AUTOSAR XML (schema 4.0)
standard types defined: float32, float64, sint16, sint32, sint8, uint16, uint32, uint8, void, boolean
package /ImplDataTypes
  7 x impl type, all with category=TYPE_REFERENCE, type-emitter=RTE:
    IoWeightSensorReadingType: implementation-data-type=uint16
    IopositionSensorReadingType: implementation-data-type=uint8
    SeatControlBtnImpType: implementation-data-type=uint8
    SeatControlDataImpType: implementation-data-type=uint8
    SensorPositionType: implementation-data-type=uint8
    SensorWeightType: implementation-data-type=uint8
    SepMotorStepType: implementation-data-type=sint8
package /MappingSets
  data type mapping set MappingSet
package /PortInterfaces/ClientServer
  6 x client server interface:
    CsIf_IoGetSensorPosition
      operation IoGetHeight
        arg Position: type=IopositionSensorReadingType, direction=OUT
      operation IoGetIncline
        arg Position: type=IopositionSensorReadingType, direction=OUT
      operation IoGetSlide
        arg Position: type=IopositionSensorReadingType, direction=OUT
    CsIf_IoGetSensorweight
      operation IoGetWeight
        arg weight: type=IoWeightSensorReadingType, direction=OUT
    CsIf_IoSetMotor
      6 x operation:
        IoSetHeightForward
        IoSetHeightReverse
        IoSetInclineForward
        IoSetInclineReverse
        IoSetSlideForward
        IoSetSlideReverse
    CsIf_PositionSensor
      operation GetHeightPosition
        arg Position: type=SensorPositionType, direction=OUT
      operation GetInclinePosition
        arg Position: type=SensorPositionType, direction=OUT
      operation GetSlidePosition
        arg Position: type=SensorPositionType, direction=OUT
    CsIf_StepMotor
      operation HeightMotor_Move
        arg Step: type=SepMotorStepType, direction=IN
      operation InclineMotor_Move
        arg Step: type=SepMotorStepType, direction=IN
      operation SlideMotor_Move
        arg Step: type=SepMotorStepType, direction=IN
    CsIf_WeightSensor
      operation GetWeight
        arg Weight: type=SensorWeightType, direction=OUT
package /PortInterfaces/SenderReceiver
  sender receiver interface Srlf_SeatControlBtnstate
    data HeightBtnState: type=SeatControlBtnImpType
    data InclineBtnState: type=SeatControlBtnImpType
    data SlideBtnState: type=SeatControlBtnImpType
  sender receiver interface Srlf_SeatControlData
    data HeightCtrlData: type=SeatControlDataImpType
    data InclineCtrlData: type=SeatControlDataImpType
    data SlideCtrlData: type=SeatControlDataImpType
package /SoftwareComponents
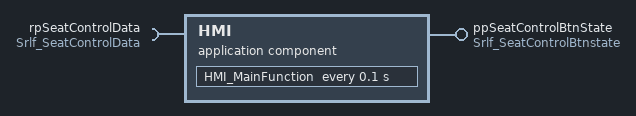
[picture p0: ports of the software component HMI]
  application sw component type HMI
    provide port ppSeatControlBtnState: provided-interface=Srlf_SeatControlBtnstate
    require port rpSeatControlData: required-interface=Srlf_SeatControlData
    behavior Ibhv_HMI: data-type-mapping=MappingSet, handle-termination-and-restart=NO-SUPPORT
      timing event TE_HMI_MainFunction_100ms: start-on-event=HMI_MainFunction, period=0.1
      runnable HMI_MainFunction
        data-receive-point-by-arguments:
          access DRP_rpSeatControlData_HeightCtrlData: accessed-variable=rpSeatControlData.HeightCtrlData
          access DRP_rpSeatControlData_InclineCtrlData: accessed-variable=rpSeatControlData.InclineCtrlData
          access DRP_rpSeatControlData_SlideCtrlData: accessed-variable=rpSeatControlData.SlideCtrlData
        data-send-points:
          access DSP_ppSeatControlBtnState_HeightBtnState: accessed-variable=ppSeatControlBtnState.HeightBtnState
          access DSP_ppSeatControlBtnState_InclineBtnState: accessed-variable=ppSeatControlBtnState.InclineBtnState
          access DSP_ppSeatControlBtnState_SlideBtnState: accessed-variable=ppSeatControlBtnState.SlideBtnState
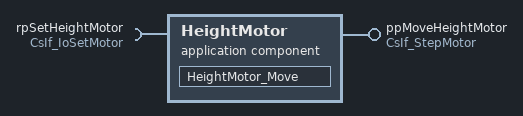
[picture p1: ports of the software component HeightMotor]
  application sw component type HeightMotor
    provide port ppMoveHeightMotor: provided-interface=CsIf_StepMotor
    require port rpSetHeightMotor: required-interface=CsIf_IoSetMotor
    behavior Ibhv_HeightMotor: data-type-mapping=MappingSet, handle-termination-and-restart=NO-SUPPORT
      operation invoked event OIE_ppMoveHeightMotor_HeightMotor_Move: start-on-event=HeightMotor_Move, operation=ppMoveHeightMotor.HeightMotor_Move
      runnable HeightMotor_Move
        sync call SCP_rpSetHeightMotor_IoSetHeightForward: operation=rpSetHeightMotor.IoSetHeightForward, timeout=0.0
        sync call SCP_rpSetHeightMotor_IoSetHeightReverse: operation=rpSetHeightMotor.IoSetHeightReverse, timeout=0.0
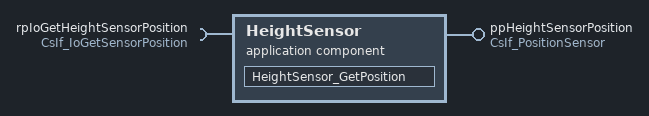
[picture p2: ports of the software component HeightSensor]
  application sw component type HeightSensor
    provide port ppHeightSensorPosition: provided-interface=CsIf_PositionSensor
    require port rpIoGetHeightSensorPosition: required-interface=CsIf_IoGetSensorPosition
    behavior Ibhv_HeightSensor: data-type-mapping=MappingSet, handle-termination-and-restart=NO-SUPPORT
      operation invoked event OIE_ppHeightSensorPosition_GetHeightPosition: start-on-event=HeightSensor_GetPosition, operation=ppHeightSensorPosition.GetHeightPosition
      runnable HeightSensor_GetPosition
        sync call SCP_rpIoGetHeightSensorPosition_IoGetHeight: operation=rpIoGetHeightSensorPosition.IoGetHeight, timeout=0.0
  10 x swc implementation, all with programming-language=C, sw-version=1.0.0, vendor-id=255:
    Impl_HMI: behavior=Ibhv_HMI
      code-descriptors:
        code Code: artifact-descriptors=autosar-engineering-object={short-label=SWC.c, category=SWSRC}
      resource consumption ResourceConsumption
    Impl_HeightMotor: behavior=Ibhv_HeightMotor
      code-descriptors:
        code Code: artifact-descriptors=autosar-engineering-object={short-label=SWC.c, category=SWSRC}
      resource consumption ResourceConsumption
    Impl_HeightSensor: behavior=Ibhv_HeightSensor
      code-descriptors:
        code Code: artifact-descriptors=autosar-engineering-object={short-label=SWC.c, category=SWSRC}
      resource consumption ResourceConsumption
    Impl_InclineMotor: behavior=Ibhv_InclineMotor
      code-descriptors:
        code Code: artifact-descriptors=autosar-engineering-object={short-label=SWC.c, category=SWSRC}
      resource consumption ResourceConsumption
    Impl_InclineSensor: behavior=Ibhv_InclineSensor
      code-descriptors:
        code Code: artifact-descriptors=autosar-engineering-object={short-label=SWC.c, category=SWSRC}
      resource consumption ResourceConsumption
    Impl_IoHwAbs: behavior=Ibhv_IoHwAbs
      code-descriptors:
        code Code: artifact-descriptors=autosar-engineering-object={short-label=SWC.c, category=SWSRC}
      resource consumption ResourceConsumption
    Impl_Seat_Manager: behavior=Ibhv_Seat_Manager
      code-descriptors:
        code Code: artifact-descriptors=autosar-engineering-object={short-label=SWC.c, category=SWSRC}
      resource consumption ResourceConsumption
    Impl_SlideMotor: behavior=Ibhv_SlideMotor
      code-descriptors:
        code Code: artifact-descriptors=autosar-engineering-object={short-label=SWC.c, category=SWSRC}
      resource consumption ResourceConsumption
    Impl_SlideSensor: behavior=Ibhv_SlideSensor
      code-descriptors:
        code Code: artifact-descriptors=autosar-engineering-object={short-label=SWC.c, category=SWSRC}
      resource consumption ResourceConsumption
    Impl_WeightSensor: behavior=Ibhv_WeightSensor
      code-descriptors:
        code Code: artifact-descriptors=autosar-engineering-object={short-label=SWC.c, category=SWSRC}
      resource consumption ResourceConsumption
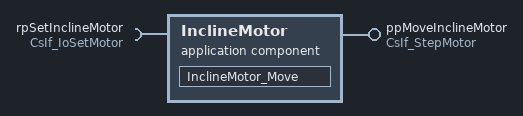
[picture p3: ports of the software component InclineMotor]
  application sw component type InclineMotor
    provide port ppMoveInclineMotor: provided-interface=CsIf_StepMotor
    require port rpSetInclineMotor: required-interface=CsIf_IoSetMotor
    behavior Ibhv_InclineMotor: data-type-mapping=MappingSet, handle-termination-and-restart=NO-SUPPORT
      operation invoked event OIE_ppMoveInclineMotor_InclineMotor_Move: start-on-event=InclineMotor_Move, operation=ppMoveInclineMotor.InclineMotor_Move
      runnable InclineMotor_Move
        sync call SCP_rpSetInclineMotor_IoSetInclineForward: operation=rpSetInclineMotor.IoSetInclineForward, timeout=0.0
        sync call SCP_rpSetInclineMotor_IoSetInclineReverse: operation=rpSetInclineMotor.IoSetInclineReverse, timeout=0.0
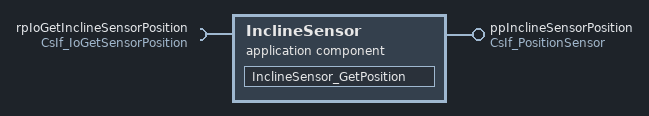
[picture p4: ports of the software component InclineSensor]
  application sw component type InclineSensor
    provide port ppInclineSensorPosition: provided-interface=CsIf_PositionSensor
    require port rpIoGetInclineSensorPosition: required-interface=CsIf_IoGetSensorPosition
    behavior Ibhv_InclineSensor: data-type-mapping=MappingSet, handle-termination-and-restart=NO-SUPPORT
      operation invoked event OIE_ppInclineSensorPosition_GetInclinePosition: start-on-event=InclineSensor_GetPosition, operation=ppInclineSensorPosition.GetInclinePosition
      runnable InclineSensor_GetPosition
        sync call SCP_rpIoGetInclineSensorPosition_IoGetIncline: operation=rpIoGetInclineSensorPosition.IoGetIncline, timeout=0.0
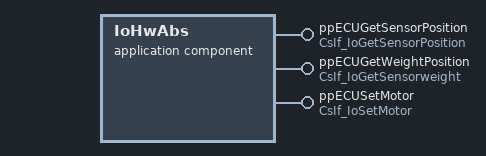
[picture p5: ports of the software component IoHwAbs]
  application sw component type IoHwAbs
    provide port ppECUGetSensorPosition: provided-interface=CsIf_IoGetSensorPosition
    provide port ppECUGetWeightPosition: provided-interface=CsIf_IoGetSensorweight
    provide port ppECUSetMotor: provided-interface=CsIf_IoSetMotor
    behavior Ibhv_IoHwAbs: data-type-mapping=MappingSet, handle-termination-and-restart=NO-SUPPORT
      10 x operation invoked event:
        OIE_ppECUGetSensorPosition_IoGetHeight: start-on-event=IoHwAbs_ECUGet_Height, operation=ppECUGetSensorPosition.IoGetHeight
        OIE_ppECUGetSensorPosition_IoGetIncline: start-on-event=IoHwAbs_ECUGet_Incline, operation=ppECUGetSensorPosition.IoGetIncline
        OIE_ppECUGetSensorPosition_IoGetSlide: start-on-event=IoHwAbs_ECUGet_Slide, operation=ppECUGetSensorPosition.IoGetSlide
        OIE_ppECUGetWeightPosition_IoGetWeight: start-on-event=IoHwAbs_ECUGet_Weight, operation=ppECUGetWeightPosition.IoGetWeight
        OIE_ppECUSetMotor_IoSetHeightForward: start-on-event=IoHwAbs_ECUGet_Setforward_Height, operation=ppECUSetMotor.IoSetHeightForward
        OIE_ppECUSetMotor_IoSetHeightReverse: start-on-event=IoHwAbs_ECUGet_SetReverse_Height, operation=ppECUSetMotor.IoSetHeightReverse
        OIE_ppECUSetMotor_IoSetInclineForward: start-on-event=IoHwAbs_ECUGet_Setforward_Incline, operation=ppECUSetMotor.IoSetInclineForward
        OIE_ppECUSetMotor_IoSetInclineReverse: start-on-event=IoHwAbs_ECUGet_SetReverse_Incline, operation=ppECUSetMotor.IoSetInclineReverse
        OIE_ppECUSetMotor_IoSetSlideForward: start-on-event=IoHwAbs_ECUGet_Setforward_Slide, operation=ppECUSetMotor.IoSetSlideForward
        OIE_ppECUSetMotor_IoSetSlideReverse: start-on-event=IoHwAbs_ECUGet_SetReverse_Slide, operation=ppECUSetMotor.IoSetSlideReverse
      10 x runnable:
        IoHwAbs_ECUGet_Height
        IoHwAbs_ECUGet_Incline
        IoHwAbs_ECUGet_SetReverse_Height
        IoHwAbs_ECUGet_SetReverse_Incline
        IoHwAbs_ECUGet_SetReverse_Slide
        IoHwAbs_ECUGet_Setforward_Height
        IoHwAbs_ECUGet_Setforward_Incline
        IoHwAbs_ECUGet_Setforward_Slide
        IoHwAbs_ECUGet_Slide
        IoHwAbs_ECUGet_Weight
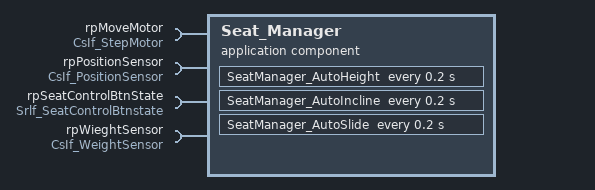
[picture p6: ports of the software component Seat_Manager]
  application sw component type Seat_Manager
    4 x require port:
      rpMoveMotor: required-interface=CsIf_StepMotor
      rpPositionSensor: required-interface=CsIf_PositionSensor
      rpSeatControlBtnState: required-interface=Srlf_SeatControlBtnstate
      rpWieghtSensor: required-interface=CsIf_WeightSensor
    behavior Ibhv_Seat_Manager: data-type-mapping=MappingSet, handle-termination-and-restart=NO-SUPPORT
      data received event DRE_rpSeatControlBtnState_HeightBtnState: start-on-event=SeatManager_SetHeight, data=rpSeatControlBtnState.HeightBtnState
      data received event DRE_rpSeatControlBtnState_InclineBtnState: start-on-event=SeatManager_SetIncline, data=rpSeatControlBtnState.InclineBtnState
      data received event DRE_rpSeatControlBtnState_SlideBtnState: start-on-event=SeatManager_SetSlide, data=rpSeatControlBtnState.SlideBtnState
      timing event TE_SeatManager_AutoHeight_200ms: start-on-event=SeatManager_AutoHeight, period=0.2
      timing event TE_SeatManager_AutoIncline_200ms: start-on-event=SeatManager_AutoIncline, period=0.2
      timing event TE_SeatManager_AutoSlide_200ms: start-on-event=SeatManager_AutoSlide, period=0.2
      6 x runnable:
        SeatManager_AutoHeight
          sync call SCP_rpMoveMotor_HeightMotor_Move: operation=rpMoveMotor.HeightMotor_Move, timeout=0.0
          sync call SCP_rpPositionSensor_GetHeightPosition: operation=rpPositionSensor.GetHeightPosition, timeout=0.0
          sync call SCP_rpWieghtSensor_GetWeight: operation=rpWieghtSensor.GetWeight, timeout=0.0
        SeatManager_AutoIncline
          sync call SCP_rpMoveMotor_InclineMotor_Move: operation=rpMoveMotor.InclineMotor_Move, timeout=0.0
          sync call SCP_rpPositionSensor_GetInclinePosition: operation=rpPositionSensor.GetInclinePosition, timeout=0.0
          sync call SCP_rpWieghtSensor_GetWeight: operation=rpWieghtSensor.GetWeight, timeout=0.0
        SeatManager_AutoSlide
          sync call SCP_rpMoveMotor_SlideMotor_Move: operation=rpMoveMotor.SlideMotor_Move, timeout=0.0
          sync call SCP_rpPositionSensor_GetSlidePosition: operation=rpPositionSensor.GetSlidePosition, timeout=0.0
          sync call SCP_rpWieghtSensor_GetWeight: operation=rpWieghtSensor.GetWeight, timeout=0.0
        SeatManager_SetHeight
          data-receive-point-by-arguments:
            access DRP_rpSeatControlBtnState_HeightBtnState: accessed-variable=rpSeatControlBtnState.HeightBtnState
          sync call SCP_rpMoveMotor_HeightMotor_Move: operation=rpMoveMotor.HeightMotor_Move, timeout=0.0
        SeatManager_SetIncline
          data-receive-point-by-arguments:
            access DRP_rpSeatControlBtnState_InclineBtnState: accessed-variable=rpSeatControlBtnState.InclineBtnState
          sync call SCP_rpMoveMotor_InclineMotor_Move: operation=rpMoveMotor.InclineMotor_Move, timeout=0.0
        SeatManager_SetSlide
          data-receive-point-by-arguments:
            access DRP_rpSeatControlBtnState_SlideBtnState: accessed-variable=rpSeatControlBtnState.SlideBtnState
          sync call SCP_rpMoveMotor_SlideMotor_Move: operation=rpMoveMotor.SlideMotor_Move, timeout=0.0
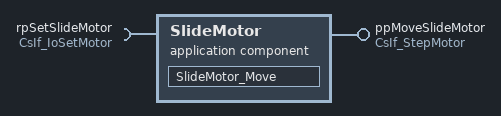
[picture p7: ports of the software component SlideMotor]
  application sw component type SlideMotor
    provide port ppMoveSlideMotor: provided-interface=CsIf_StepMotor
    require port rpSetSlideMotor: required-interface=CsIf_IoSetMotor
    behavior Ibhv_SlideMotor: data-type-mapping=MappingSet, handle-termination-and-restart=NO-SUPPORT
      operation invoked event OIE_ppMoveSlideMotor_SlideMotor_Move: start-on-event=SlideMotor_Move, operation=ppMoveSlideMotor.SlideMotor_Move
      runnable SlideMotor_Move
        sync call SCP_rpSetSlideMotor_IoSetSlideForward: operation=rpSetSlideMotor.IoSetSlideForward, timeout=0.0
        sync call SCP_rpSetSlideMotor_IoSetSlideReverse: operation=rpSetSlideMotor.IoSetSlideReverse, timeout=0.0
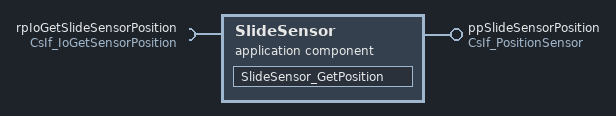
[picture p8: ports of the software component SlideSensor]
  application sw component type SlideSensor
    provide port ppSlideSensorPosition: provided-interface=CsIf_PositionSensor
    require port rpIoGetSlideSensorPosition: required-interface=CsIf_IoGetSensorPosition
    behavior Ibhv_SlideSensor: data-type-mapping=MappingSet, handle-termination-and-restart=NO-SUPPORT
      operation invoked event OIE_ppSlideSensorPosition_GetSlidePosition: start-on-event=SlideSensor_GetPosition, operation=ppSlideSensorPosition.GetSlidePosition
      runnable SlideSensor_GetPosition
        sync call SCP_rpIoGetSlideSensorPosition_IoGetSlide: operation=rpIoGetSlideSensorPosition.IoGetSlide, timeout=0.0
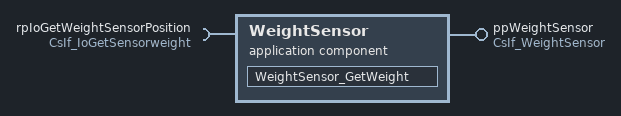
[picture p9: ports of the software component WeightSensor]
  application sw component type WeightSensor
    provide port ppWeightSensor: provided-interface=CsIf_WeightSensor
    require port rpIoGetWeightSensorPosition: required-interface=CsIf_IoGetSensorweight
    behavior Ibhv_WeightSensor: data-type-mapping=MappingSet, handle-termination-and-restart=NO-SUPPORT
      operation invoked event OIE_ppWeightSensor_GetWeight: start-on-event=WeightSensor_GetWeight, operation=ppWeightSensor.GetWeight
      runnable WeightSensor_GetWeight
        sync call SCP_rpIoGetWeightSensorPosition_IoGetWeight: operation=rpIoGetWeightSensorPosition.IoGetWeight, timeout=0.0
package /Compositions
  composition sw component type TaskComposition
    9 x component:
      HMI: type=HMI
      HeightMotor: type=HeightMotor
      HeightSensor: type=HeightSensor
      InclineMotor: type=InclineMotor
      InclineSensor: type=InclineSensor
      Seat_Manager: type=Seat_Manager
      SlideMotor: type=SlideMotor
      SlideSensor: type=SlideSensor
      WeightSensor: type=WeightSensor
    connect HMI.ppSeatControlBtnState -> Seat_Manager.rpSeatControlBtnState
    connect HeightMotor.ppMoveHeightMotor -> Seat_Manager.rpMoveMotor
    connect HeightSensor.ppHeightSensorPosition -> Seat_Manager.rpPositionSensor
    connect InclineMotor.ppMoveInclineMotor -> Seat_Manager.rpMoveMotor
    connect InclineSensor.ppInclineSensorPosition -> Seat_Manager.rpPositionSensor
    connect SlideMotor.ppMoveSlideMotor -> Seat_Manager.rpMoveMotor
    connect SlideSensor.ppSlideSensorPosition -> Seat_Manager.rpPositionSensor
    connect WeightSensor.ppWeightSensor -> Seat_Manager.rpWieghtSensor
